# MWONECLR register map
Vendor: SYNTH-Corp; File version: 1.0
oneToClear (write-1-to-clear) fixture
CPU: CM4 r0p1, little endian
Registers are access not given, reset 0x0 unless marked. A register's access mark holds for its fields unless they carry their own. Offsets are from the block's base; lines under a group give offsets from that group; [hi:lo] are bit positions; {n}, {i} and the like mark numbered series; 'fields as' and 'values as' point back to an identical list; <NAME> marks a mode.

## Memory map
0x40034000 UART0 size 0x100 — UART with interrupt-clear register

## UART0 — UART with interrupt-clear register
Base 0x40034000
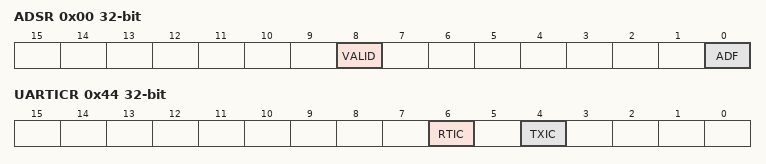
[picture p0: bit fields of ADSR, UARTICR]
0x00 ADSR — Mixed-semantics status register
  [8] VALID — Valid sample
  [0] ADF write-1-clears — ADC finished flag (write 1 to clear)
0x04 UARTDR — Plain read-write data register
0x10 PERF write-1-clears — Register-level oneToClear counter
  [15:0] CNT — Counter
0x44 UARTICR — Interrupt clear register (write 1 to clear)
  [6] RTIC write-1-clears — Clear RX timeout interrupt
  [4] TXIC write-1-clears — Clear TX interrupt
